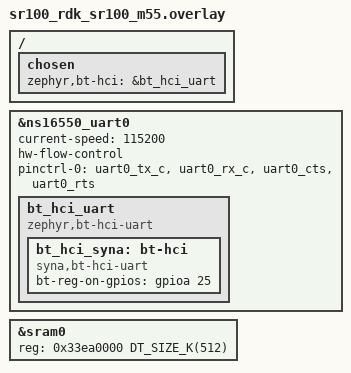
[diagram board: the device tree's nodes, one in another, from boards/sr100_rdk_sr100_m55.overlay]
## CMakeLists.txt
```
# Copyright (c) 2026 Synaptics Incorporated
#
# SPDX-License-Identifier: Apache-2.0

cmake_minimum_required(VERSION 3.20.0)
find_package(Zephyr REQUIRED HINTS $ENV{ZEPHYR_BASE})
project(bap_unicast_server_broadcast_sink)

# src/ must be FIRST so local stub headers (lc3.h, usb.h) shadow upstream ones
target_include_directories(app PRIVATE
	src/
	$ENV{ZEPHYR_BASE}/samples/bluetooth/bap_unicast_server/src/
	$ENV{ZEPHYR_BASE}/samples/bluetooth/bap_broadcast_sink/src/
)

target_sources(app PRIVATE
	src/main.c
	# Unicast server TX (not used for SNK-only, but required by stream_tx.c)
	$ENV{ZEPHYR_BASE}/samples/bluetooth/bap_unicast_server/src/stream_tx.c
	src/stream_lc3.c
	# Broadcast sink RX (ISO packet counting / LC3 stub decode)
	$ENV{ZEPHYR_BASE}/samples/bluetooth/bap_broadcast_sink/src/stream_rx.c
	# SR110 stubs (shadow upstream hw_codec.c / lc3.c / usb.c)
	src/lc3.c
	src/hw_codec.c
	src/usb.c
)
```

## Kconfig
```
# Copyright (c) 2026 Synaptics Incorporated
#
# SPDX-License-Identifier: Apache-2.0

mainmenu "Bluetooth: BAP Unicast Server + Broadcast Sink"

# ── Broadcast Sink scan options ──────────────────────────────────────────────

config SCAN_OFFLOAD
	bool "Wait for a Broadcast Assistant before scanning"
	default n

config SCAN_SELF
	bool "Scan for Broadcast Sources without a Broadcast Assistant"
	default y

config SCAN_DELAY
	int "Delay before starting scan (seconds)"
	range 0 255
	default 5
	depends on SCAN_SELF

config TARGET_BROADCAST_NAME
	string "Target Broadcast Device Name substring (empty = any)"
	default ""

config MAX_CODEC_FRAMES_PER_SDU
	int "Maximum codec frames per SDU"
	default 1
	range 1 255

config ENABLE_LC3
	bool "Enable LC3 codec decoding"
	default n

config USE_USB_AUDIO_OUTPUT
	bool "Use USB Audio as output"
	default n

config USE_CODEC_AUDIO_OUTPUT
	bool "Use Codec Audio as output"
	default n

config USE_SPECIFIC_BROADCAST_CHANNEL
	bool "Sync to a specific Broadcast Channel Audio Location"
	default n

config TARGET_BROADCAST_CHANNEL
	int "Broadcast Channel Audio Location to sync to"
	range 0 3
	default 1
	depends on USE_SPECIFIC_BROADCAST_CHANNEL

config INFO_REPORTING_INTERVAL
	int "SDUs received between each report (0 = disabled)"
	default 1000

source "Kconfig.zephyr"
```

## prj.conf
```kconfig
CONFIG_BT=y
CONFIG_LOG=y
CONFIG_UTF8=y
CONFIG_BT_SMP=y
CONFIG_BT_BONDABLE=y
CONFIG_BT_KEYS_OVERWRITE_OLDEST=y

# ── Unicast Server ──────────────────────────────────────────────────────────
CONFIG_BT_PERIPHERAL=y
CONFIG_BT_GAP_AUTO_UPDATE_CONN_PARAMS=n
CONFIG_BT_PERIPHERAL_PREF_MIN_INT=50
CONFIG_BT_PERIPHERAL_PREF_MAX_INT=70
CONFIG_BT_PERIPHERAL_PREF_LATENCY=0
CONFIG_BT_PERIPHERAL_PREF_TIMEOUT=400
CONFIG_BT_ISO_PERIPHERAL=y
CONFIG_BT_AUDIO=y
CONFIG_BT_CAP_ACCEPTOR=y
CONFIG_BT_GATT_DYNAMIC_DB=y
CONFIG_BT_BAP_UNICAST_SERVER=y
CONFIG_BT_ASCS=y
CONFIG_BT_PAC_SNK=y
CONFIG_BT_ASCS_MAX_ASE_SNK_COUNT=2
CONFIG_BT_PAC_SRC=y
CONFIG_BT_ASCS_MAX_ASE_SRC_COUNT=0
CONFIG_BT_ISO_TX_BUF_COUNT=2
CONFIG_BT_AUDIO_CODEC_CFG_MAX_METADATA_SIZE=255
CONFIG_BT_ATT_PREPARE_COUNT=8

# ── Broadcast Sink ──────────────────────────────────────────────────────────
CONFIG_BT_OBSERVER=y
CONFIG_BT_PER_ADV_SYNC=y
CONFIG_BT_ISO_SYNC_RECEIVER=y
CONFIG_BT_BAP_BROADCAST_SINK=y
CONFIG_BT_BAP_SCAN_DELEGATOR=y
CONFIG_BT_BAP_SCAN_DELEGATOR_RECV_STATE_COUNT=3
CONFIG_BT_ISO_RX_BUF_COUNT=8
CONFIG_BT_BAP_BROADCAST_SNK_SUBGROUP_COUNT=1
CONFIG_BT_BAP_BROADCAST_SNK_STREAM_COUNT=2
CONFIG_BT_BAP_BASS_MAX_SUBGROUPS=1

# ── ISO shared ──────────────────────────────────────────────────────────────
CONFIG_BT_ISO_MAX_CHAN=4
CONFIG_BT_EXT_ADV=y
CONFIG_BT_BUF_ACL_RX_SIZE=255
CONFIG_BT_BUF_ACL_TX_SIZE=251
CONFIG_BT_AUDIO_CODEC_CFG_MAX_DATA_SIZE=64
CONFIG_BT_AUDIO_CODEC_CAP_MAX_DATA_SIZE=64
CONFIG_BT_AUDIO_CODEC_CAP_MAX_METADATA_SIZE=255

CONFIG_BT_DEVICE_NAME="SR110 LE Audio"

# ── SR110 + SYNA hardware ───────────────────────────────────────────────────
CONFIG_BT_H4=y
CONFIG_BT_HCI_SYNA=y
CONFIG_GPIO=y
CONFIG_UART_INTERRUPT_DRIVEN=y
CONFIG_UART_NS16550_VARIANT_NS16750=y
CONFIG_SRAM_SIZE=512
CONFIG_MAIN_STACK_SIZE=12288
CONFIG_BT_RX_STACK_SIZE=8192
CONFIG_SYSTEM_WORKQUEUE_STACK_SIZE=4096
CONFIG_BT_BUF_CMD_TX_SIZE=255
CONFIG_STACK_SENTINEL=y
CONFIG_LOG_PRINTK=n
CONFIG_XIP=n
```

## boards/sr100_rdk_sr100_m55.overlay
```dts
/*
 * Copyright (c) 2026 Synaptics Incorporated
 *
 * SPDX-License-Identifier: Apache-2.0
 */

/ {
	chosen {
		zephyr,bt-hci = &bt_hci_uart;
	};
};

&ns16550_uart0 {
	status = "okay";
	current-speed = <115200>;
	hw-flow-control;
	pinctrl-0 = <&uart0_tx_c &uart0_rx_c &uart0_cts &uart0_rts>;
	pinctrl-names = "default";

	bt_hci_uart: bt_hci_uart {
		compatible = "zephyr,bt-hci-uart";
		status = "okay";

		bt_hci_syna: bt-hci {
			compatible = "syna,bt-hci-uart";
			status = "okay";
			bt-reg-on-gpios = <&gpioa 25 GPIO_ACTIVE_HIGH>;
		};
	};
};

&sram0 {
	reg = <0x33ea0000 DT_SIZE_K(512)>;
	ranges = <0x0 0x33ea0000 DT_SIZE_K(512)>;
};
```

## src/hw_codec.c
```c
/*
 * Copyright (c) 2026 Synaptics Incorporated
 *
 * SPDX-License-Identifier: Apache-2.0
 */

#include <stddef.h>
#include <stdint.h>
#include "hw_codec.h"

int hw_codec_open(void) { return 0; }
int hw_codec_cfg(uint32_t samplerate) { (void)samplerate; return 0; }
uint32_t hw_codec_write_data(const uint8_t *data, uint32_t len) { (void)data; return len; }
int hw_codec_close(void) { return 0; }
```

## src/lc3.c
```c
/*
 * Copyright (c) 2026 Synaptics Incorporated
 *
 * SPDX-License-Identifier: Apache-2.0
 */

#include <zephyr/sys/printk.h>
#include "lc3.h"

int lc3_init(void)
{
	printk("[lc3] stub: LC3 decoder not available on SR110\n");
	return 0;
}

int lc3_enable(struct stream_rx *stream)
{
	(void)stream;
	return 0;
}

int lc3_disable(struct stream_rx *stream)
{
	(void)stream;
	return 0;
}

void lc3_enqueue_for_decoding(struct stream_rx *stream, const struct bt_iso_recv_info *info,
			       struct net_buf *buf)
{
	(void)stream;
	(void)info;
	(void)buf;
}
```

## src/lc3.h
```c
/* Copyright (c) 2026 Synaptics Incorporated — SR110 stub: no LC3 decode on SR110 */
#ifndef SAMPLE_BAP_COMBINED_LC3_H
#define SAMPLE_BAP_COMBINED_LC3_H

#include <stdbool.h>
#include <stddef.h>
#include <stdint.h>
#include <zephyr/bluetooth/audio/audio.h>
#include <zephyr/bluetooth/iso.h>
#include <zephyr/kernel.h>
#include <zephyr/net_buf.h>
#include "stream_rx.h"

int lc3_enable(struct stream_rx *stream);
int lc3_disable(struct stream_rx *stream);
void lc3_enqueue_for_decoding(struct stream_rx *stream, const struct bt_iso_recv_info *info,
			       struct net_buf *buf);
int lc3_init(void);

#endif /* SAMPLE_BAP_COMBINED_LC3_H */
```

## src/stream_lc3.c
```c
/*
 * Copyright (c) 2026 Synaptics Incorporated
 *
 * SPDX-License-Identifier: Apache-2.0
 */

#include <errno.h>
#include <zephyr/net_buf.h>

struct tx_stream;

int stream_lc3_init(struct tx_stream *stream)
{
	(void)stream;
	return -ENOTSUP;
}

void stream_lc3_add_data(struct tx_stream *stream, struct net_buf *buf)
{
	(void)stream;
	(void)buf;
}
```

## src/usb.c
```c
/*
 * Copyright (c) 2026 Synaptics Incorporated
 *
 * SPDX-License-Identifier: Apache-2.0
 */

#include "usb.h"

int usb_init(void) { return 0; }

int usb_add_frame_to_usb(enum bt_audio_location chan_allocation, const int16_t *frame,
			  size_t frame_size, uint32_t ts)
{
	(void)chan_allocation;
	(void)frame;
	(void)frame_size;
	(void)ts;
	return 0;
}

void usb_clear_frames_to_usb(void) {}
```

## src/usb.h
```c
/* Copyright (c) 2026 Synaptics Incorporated — SR110 stub: no USB audio on SR110 */
#ifndef SAMPLE_BAP_COMBINED_USB_H
#define SAMPLE_BAP_COMBINED_USB_H

#include <stdbool.h>
#include <stddef.h>
#include <stdint.h>
#include <zephyr/bluetooth/audio/audio.h>

#define USB_SAMPLE_RATE_HZ 48000U

int usb_add_frame_to_usb(enum bt_audio_location chan_allocation, const int16_t *frame,
			  size_t frame_size, uint32_t ts);
void usb_clear_frames_to_usb(void);
int usb_init(void);

#endif /* SAMPLE_BAP_COMBINED_USB_H */
```
